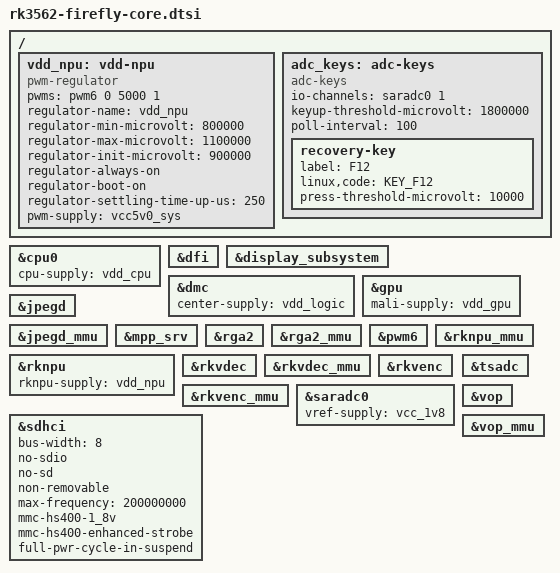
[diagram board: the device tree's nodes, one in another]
// SPDX-License-Identifier: (GPL-2.0+ OR MIT)
/*
 * Copyright (c) 2022 Rockchip Electronics Co., Ltd.
 *
 */

#include <dt-bindings/display/drm_mipi_dsi.h>
#include <dt-bindings/gpio/gpio.h>
#include <dt-bindings/input/input.h>
#include <dt-bindings/pinctrl/rockchip.h>

/ {
	vdd_npu: vdd-npu {
		compatible = "pwm-regulator";
		pwms = <&pwm6 0 5000 1>;
		regulator-name = "vdd_npu";
		regulator-min-microvolt = <800000>;
		regulator-max-microvolt = <1100000>;
		regulator-init-microvolt = <900000>;
		regulator-always-on;
		regulator-boot-on;
		regulator-settling-time-up-us = <250>;
		pwm-supply = <&vcc5v0_sys>;
		status = "okay";
	};

	adc_keys: adc-keys {
		compatible = "adc-keys";
		io-channels = <&saradc0 1>;
		io-channel-names = "buttons";
		keyup-threshold-microvolt = <1800000>;
		poll-interval = <100>;

		recovery-key {
			label = "F12";
			linux,code = <KEY_F12>;
			press-threshold-microvolt = <10000>;
		};
	};
};


&cpu0 {
	cpu-supply = <&vdd_cpu>;
};

&dfi {
	status = "okay";
};

&display_subsystem {
	status = "okay";
};

&dmc {
	center-supply = <&vdd_logic>;
	status = "okay";
};

&gpu {
	status = "okay";
	mali-supply = <&vdd_gpu>;
};

&jpegd {
	status = "okay";
};

&jpegd_mmu {
	status = "okay";
};

&mpp_srv {
	status = "okay";
};

&rga2 {
	status = "okay";
};

&rga2_mmu {
	status = "okay";
};

&pwm6 {
	status = "okay";
};

&rknpu {
	rknpu-supply = <&vdd_npu>;
	status = "okay";
};

&rknpu_mmu {
	status = "okay";
};

&rkvdec {
	status = "okay";
};

&rkvdec_mmu {
	status = "okay";
};

&rkvenc {
	status = "okay";
};

&rkvenc_mmu {
	status = "okay";
};

&saradc0 {
	status = "okay";
	vref-supply = <&vcc_1v8>;
};

&sdhci {
	bus-width = <8>;
	no-sdio;
	no-sd;
	non-removable;
	max-frequency = <200000000>;
	mmc-hs400-1_8v;
	mmc-hs400-enhanced-strobe;
	full-pwr-cycle-in-suspend;
	status = "okay";
};

&tsadc {
	status = "okay";
};

&vop {
	status = "okay";
};

&vop_mmu {
	status = "okay";
};
